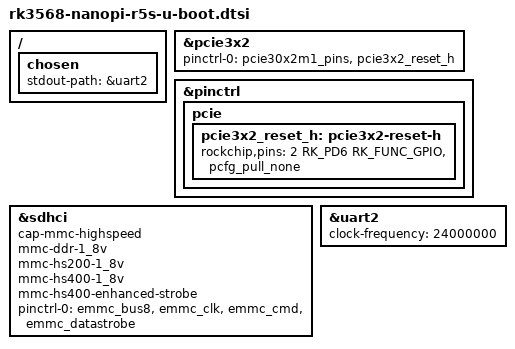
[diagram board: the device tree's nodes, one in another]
// SPDX-License-Identifier: GPL-2.0-or-later OR MIT
/*
 * Copyright (c) 2022 FriendlyElec Computer Tech. Co., Ltd.
 * (http://www.friendlyelec.com)
 *
 * Copyright (c) 2023 Tianling Shen <cnsztl@gmail.com>
 */

#include "rk356x-u-boot.dtsi"

/ {
	chosen {
		stdout-path = &uart2;
	};
};

&pcie3x2 {
	pinctrl-0 = <&pcie30x2m1_pins &pcie3x2_reset_h>;
};

&pinctrl {
	pcie {
		pcie3x2_reset_h: pcie3x2-reset-h {
			rockchip,pins = <2 RK_PD6 RK_FUNC_GPIO &pcfg_pull_none>;
		};
	};
};

&sdhci {
	cap-mmc-highspeed;
	mmc-ddr-1_8v;
	mmc-hs200-1_8v;
	mmc-hs400-1_8v;
	mmc-hs400-enhanced-strobe;
	pinctrl-0 = <&emmc_bus8 &emmc_clk &emmc_cmd &emmc_datastrobe>;
};

&uart2 {
	bootph-all;
	clock-frequency = <24000000>;
	status = "okay";
};
